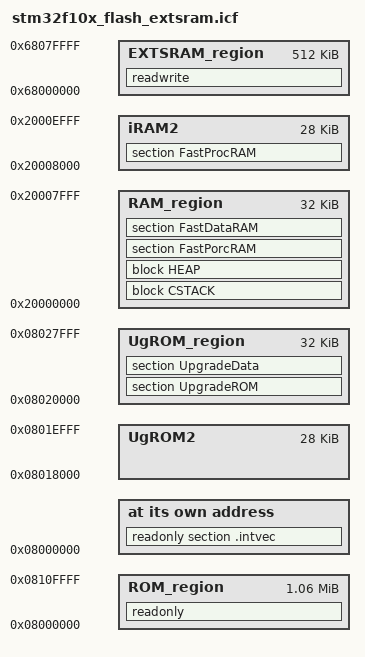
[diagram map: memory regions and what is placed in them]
/*###ICF### Section handled by ICF editor, don't touch! ****/
/*-Editor annotation file-*/
/* IcfEditorFile="$TOOLKIT_DIR$\config\ide\IcfEditor\a_v1_0.xml" */
/*-Specials-*/
define symbol __ICFEDIT_intvec_start__ = 0x08000000;
/*-Memory Regions-*/
define symbol __ICFEDIT_region_ROM_start__       = 0x08000000;
define symbol __ICFEDIT_region_ROM_end__         = 0x0810FFFF;

define symbol __ICFEDIT_region_UgROM_start__     = 0x08020000;
define symbol __ICFEDIT_region_UgROM_end__       = 0x08027FFF;



define symbol __ICFEDIT_region_RAM_start__       = 0x20000000;
define symbol __ICFEDIT_region_RAM_end__         = 0x20007FFF;
define symbol __ICFEDIT_region_EXTSRAM_start__   = 0x68000000;
define symbol __ICFEDIT_region_EXTSRAM_end__     = 0x6807FFFF;

/*-Sizes-*/
define symbol __ICFEDIT_size_cstack__   = 0x1000;
define symbol __ICFEDIT_size_heap__     = 0x200;
/**** End of ICF editor section. ###ICF###*/





define memory mem with size = 4G;
define region ROM_region      = mem:[from __ICFEDIT_region_ROM_start__   to __ICFEDIT_region_ROM_end__];
define region UgROM_region      = mem:[from __ICFEDIT_region_UgROM_start__   to __ICFEDIT_region_UgROM_end__];
define region UgROM2           = mem:[ from 0x08018000 to 0x0801EFFF];
define region RAM_region      = mem:[from __ICFEDIT_region_RAM_start__   to __ICFEDIT_region_RAM_end__];
define region iRAM2           = mem:[from 0x20008000   to 0x2000EFFF];
define region EXTSRAM_region   = mem:[from __ICFEDIT_region_EXTSRAM_start__   to __ICFEDIT_region_EXTSRAM_end__];




define block CSTACK    with alignment = 8, size = __ICFEDIT_size_cstack__   { };
define block HEAP      with alignment = 8, size = __ICFEDIT_size_heap__     { };

initialize by copy { readwrite };
initialize by copy { section FastDataRAM };
initialize by copy { section FastProcRAM };
do not initialize  { section .noinit };

place at address mem:__ICFEDIT_intvec_start__ { readonly section .intvec };

place in ROM_region     { readonly };
//place in UgROM_region   { section UpgradeROM};
//place in UgROM2         { section UpgradeData };
place in UgROM_region   { section UpgradeROM,section UpgradeData};
place in iRAM2 { section FastProcRAM }; 

place in RAM_region   { block CSTACK, block HEAP ,section FastPorcRAM,section FastDataRAM };
place in EXTSRAM_region   { readwrite };

                        
